# MIK32 register map
Vendor: Mikron; Series: MIK32; File version: 1.0
Registers are 32-bit, read-write, reset 0x0 unless marked. A register's access mark holds for its fields unless they carry their own. Offsets are from the block's base; [hi:lo] are bit positions; {n}, {i} and the like mark numbered series; 'fields as' and 'values as' point back to an identical list.

## RTC — Часы реального времени
Base 0x00060400
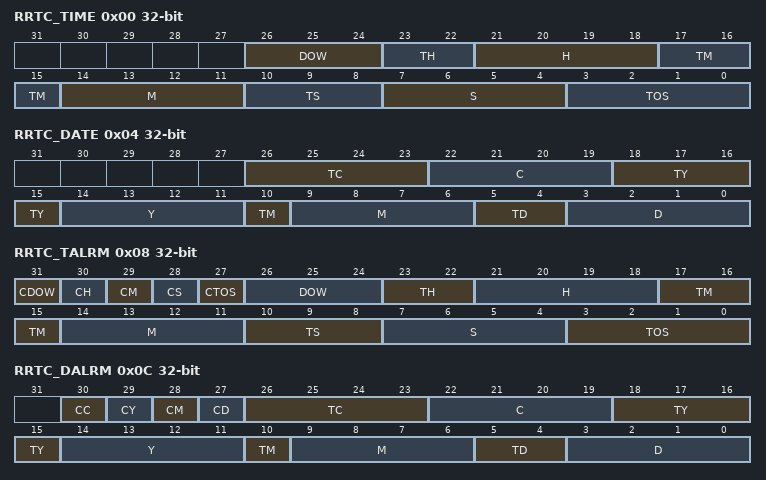
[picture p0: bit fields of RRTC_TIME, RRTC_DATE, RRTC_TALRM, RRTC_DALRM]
0x00 RRTC_TIME — Регистр установки времени. Используется BCD-кодировка
  [26:24] DOW — День недели
    1=Monday (Понедельник); 2=Tuesday (Вторник); 3=Wednesday (Среда); 4=Thursday (Четверг); 5=Friday (Пятница); 6=Saturday (Суббота); 7=Sunday (Воскресенье)
  [23:22] TH range 0..2 — Поле десятков часов. Доступные значения от 0 до 2
  [21:18] H range 0..9 — Поле единиц часов. Допустимые значения: - TH = 0 - От 0 до 9; - TH = 2 - От 0 до 3
  [17:15] TM range 0..5 — Поле десятков минут. Допустимые значения от 0 до 5
  [14:11] M range 0..9 — Поле единиц минут. Допустимые значения от 0 до 9
  [10:8] TS range 0..5 — Поле десятков секунд. Допустимые значения от 0 до 5
  [7:4] S range 0..9 — Поле единиц секунд. Допустимые значения от 0 до 9
  [3:0] TOS range 0..9 — Поле десятых долей секунды. Допустимые значения от 0 до 9
0x04 RRTC_DATE — Регистр установки даты. Используется BCD-кодировка
  [26:23] TC range 0..9 — Поле десятков веков. Допустимые значения от 0 до 9
  [22:19] C range 0..9 — Поле единиц веков. Допустимые значения от 0 до 9
  [18:15] TY range 0..9 — Поле десятков годов. Допустимые значения от 0 до 9
  [14:11] Y range 0..9 — Поле единиц годов. Допустимые значения от 0 до 9
  [10] TM — Поле десятков месяцев. Допустимые значения от 0 до 1
  [9:6] M range 0..9 — Поле единиц месяцев. Допустимые значения: - TM = 0 - от 0 до 9; - TM = 1 - от 0 до 2
  [5:4] TD — Поле десятков дней. Допустимые значения: - {TM,M} != 03 - от 0 до 3; - {TM,M} == 03 - от 0 до 2
  [3:0] D range 0..3 — Поле единиц дней. Допустимые значения: - TD = 2 - от 0 до 3; - TD = 3 - от 0 до 1
0x08 RRTC_TALRM — регистр хранит время, при совпадении которого со значением регистра RRTC_TIME, будет сгенерировано соответствующее прерывание
  [31] CDOW — Разрешает сравнения дней недели, когда установлен
    0=disabled (Сравнение дней недели отключено); 1=enable (Сравнение дней недели включено)
  [30] CH — Разрешает сравнения часов, когда установлен
    0=disabled (Сравнение часов отключено); 1=enable (Сравнение часов включено)
  [29] CM — Разрешает сравнения минут, когда установлен
    0=disabled (Сравнение минут отключено); 1=enable (Сравнение минут включено)
  [28] CS — Разрешает сравнения секунд, когда установлен
    0=disabled (Сравнение секунд отключено); 1=enable (Сравнение секунд включено)
  [27] CTOS — Разрешает сравнение десятых долей секунды, когда установлен
    0=disabled (Сравнение десятых долей секунды отключено); 1=enable (Сравнение десятых долей секунды включено)
  [26:24] DOW — День недели
    values as RRTC_TIME.DOW
  [23:22] TH range 0..2 — Поле десятков часов. Доступные значения от 0 до 2
  [21:18] H range 0..9 — Поле единиц часов. Допустимые значения: - TH = 0 - От 0 до 9; - TH = 2 - От 0 до 3
  [17:15] TM range 0..5 — Поле десятков минут. Допустимые значения от 0 до 5
  [14:11] M range 0..9 — Поле единиц минут. Допустимые значения от 0 до 9
  [10:8] TS range 0..5 — Поле десятков секунд. Допустимые значения от 0 до 5
  [7:4] S range 0..9 — Поле единиц секунд. Допустимые значения от 0 до 9
  [3:0] TOS range 0..9 — Поле десятых долей секунды. Допустимые значения от 0 до 9
0x0C RRTC_DALRM — регистр хранит время, при совпадении которого со значением регистра RRTC_TIME, будет сгенерировано соответствующее прерывание.
  [30] CC — Рразрешает сравнения веков, когда установлен
    0=disabled (Сравнение веков отключено); 1=enable (Сравнение веков включено)
  [29] CY — Разрешает сравнения годов, когда установлен
    0=disabled (Сравнение годов отключено); 1=enable (Сравнение годов включено)
  [28] CM — Разрешает сравнения месяцев, когда установлен
    0=disabled (Сравнение месяцев отключено); 1=enable (Сравнение месяцев включено)
  [27] CD — Разрешает сравнения дней, когда установлен
    0=disabled (Сравнение дней отключено); 1=enable (Сравнение дней включено)
  [26:23] TC range 0..9 — Поле десятков веков. Допустимые значения от 0 до 9
  [22:19] C range 0..9 — Поле единиц веков. Допустимые значения от 0 до 9
  [18:15] TY range 0..9 — Поле десятков годов. Допустимые значения от 0 до 9
  [14:11] Y range 0..9 — Поле единиц годов. Допустимые значения от 0 до 9
  [10] TM — Поле десятков месяцев. Допустимые значения от 0 до 1
  [9:6] M range 0..9 — Поле единиц месяцев. Допустимые значения: - TM = 0 - от 0 до 9; - TM = 1 - от 0 до 2
  [5:4] TD — Поле десятков дней. Допустимые значения: - {TM,M} != 03 - от 0 до 3; - {TM,M} == 03 - от 0 до 2
  [3:0] D range 0..3 — Поле единиц дней. Допустимые значения: - TD = 2 - от 0 до 3; - TD = 3 - от 0 до 1
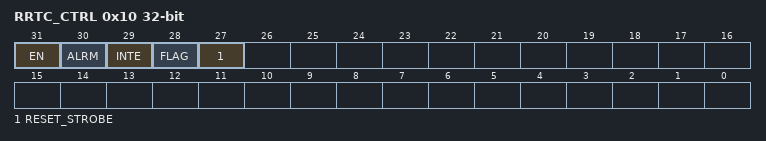
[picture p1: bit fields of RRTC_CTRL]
0x10 RRTC_CTRL — регистр управления модулем
  [31] EN — Модуль включён и производит отсчёт времени, когда установлен
    0=Disabled (Модуль отключен); 1=Enable (Модуль включен)
  [30] ALRM — Установленный бит свидетельствует о совпадении одного разрешенного или всех разрешённых полей будильника. Бит необходимо сбрасывать при помощи управляющего ПО
    0=Inactive (Будильник не сработал); 1=Active (Будильник сработал)
  [29] INTE — Бит разрешения прерывания на выходах irq и irq_async. Прерывания появляются при наличии установленного бита ALRM
    0=Disabled (Прерывания блока запрещены); 1=Enable (Прерывания блока разрешены)
  [28] FLAG ro — Сигнал проведения синхронизации между тактовыми доменами. После записи в любой регистр и пока данный бит читается равным «1», запрещено выполнять любую новую запись
    0=Ready (Запись в регистры разрешена); 1=Synchronization (Выполняется синхронизация, запись в регистры запрещена)
  [27] RESET_STROBE wo — Запись 1 сбрасывает строб будильника
    1=Reset (Сброс строба будильника)
{0x20+4i} RRTC_REG{i} (i=0..15) — Регистры общего назначения REG{i}

## Notices in the file
MIT License
Copyright (c) 2024 Лаборатория системных разработок, Mikron
Permission is hereby granted, free of charge, to any person obtaining a copy
of this software and associated documentation files (the "Software"), to deal
in the Software without restriction, including without limitation the rights
to use, copy, modify, merge, publish, distribute, sublicense, and/or sell
copies of the Software, and to permit persons to whom the Software is
furnished to do so, subject to the following conditions:
The above copyright notice and this permission notice shall be included in all
copies or substantial portions of the Software.
THE SOFTWARE IS PROVIDED "AS IS", WITHOUT WARRANTY OF ANY KIND, EXPRESS OR
IMPLIED, INCLUDING BUT NOT LIMITED TO THE WARRANTIES OF MERCHANTABILITY,
FITNESS FOR A PARTICULAR PURPOSE AND NONINFRINGEMENT. IN NO EVENT SHALL THE
AUTHORS OR COPYRIGHT HOLDERS BE LIABLE FOR ANY CLAIM, DAMAGES OR OTHER
LIABILITY, WHETHER IN AN ACTION OF CONTRACT, TORT OR OTHERWISE, ARISING FROM,
OUT OF OR IN CONNECTION WITH THE SOFTWARE OR THE USE OR OTHER DEALINGS IN THE
SOFTWARE.
